AUTOSAR XML (schema 4-0-3)
package /ComponentTypes
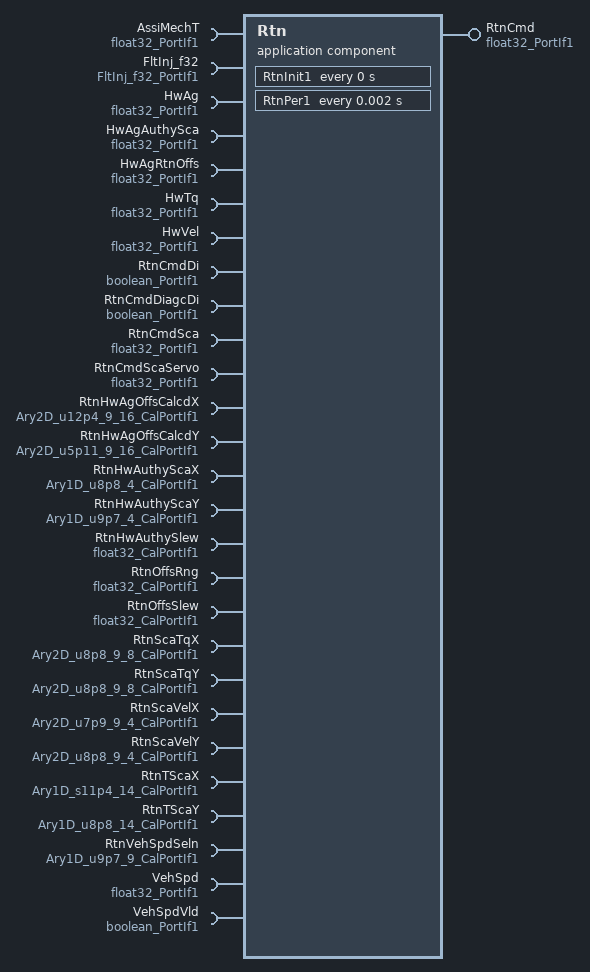
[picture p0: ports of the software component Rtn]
  application sw component type Rtn
    provide port RtnCmd: nonqueued-sender-com-spec{data-element=Val, init-value=0}, provided-interface=float32_PortIf1
    27 x require port:
      AssiMechT: nonqueued-receiver-com-spec{data-element=Val, filter=data-filter-type=ALWAYS, init-value=0}, required-interface=float32_PortIf1
      FltInj_f32: client-com-spec=Oper, required-interface=FltInj_f32_PortIf1
      HwAg: nonqueued-receiver-com-spec{data-element=Val, filter=data-filter-type=ALWAYS, init-value=0}, required-interface=float32_PortIf1
      HwAgAuthySca: nonqueued-receiver-com-spec{data-element=Val, filter=data-filter-type=ALWAYS, init-value=0}, required-interface=float32_PortIf1
      HwAgRtnOffs: nonqueued-receiver-com-spec{data-element=Val, filter=data-filter-type=ALWAYS, init-value=0}, required-interface=float32_PortIf1
      HwTq: nonqueued-receiver-com-spec{data-element=Val, filter=data-filter-type=ALWAYS, init-value=0}, required-interface=float32_PortIf1
      HwVel: nonqueued-receiver-com-spec{data-element=Val, filter=data-filter-type=ALWAYS, init-value=0}, required-interface=float32_PortIf1
      RtnCmdDi: nonqueued-receiver-com-spec{data-element=Logl, filter=data-filter-type=ALWAYS, init-value=0}, required-interface=boolean_PortIf1
      RtnCmdDiagcDi: nonqueued-receiver-com-spec{data-element=Logl, filter=data-filter-type=ALWAYS, init-value=1}, required-interface=boolean_PortIf1
      RtnCmdSca: nonqueued-receiver-com-spec{data-element=Val, filter=data-filter-type=ALWAYS, init-value=1}, required-interface=float32_PortIf1
      RtnCmdScaServo: nonqueued-receiver-com-spec{data-element=Val, filter=data-filter-type=ALWAYS, init-value=1}, required-interface=float32_PortIf1
      RtnHwAgOffsCalcdX: parameter-require-com-spec{init-value=9 x [0, 8, 16, 80, 160, 320, 480, 720, 960, 1440, 1920, 2880, 4320, 5760, 7200, 8640], parameter=Ary2D}, required-interface=Ary2D_u12p4_9_16_CalPortIf1
      RtnHwAgOffsCalcdY: parameter-require-com-spec{init-value=9 x 16 x 0, parameter=Ary2D}, required-interface=Ary2D_u5p11_9_16_CalPortIf1
      RtnHwAuthyScaX: parameter-require-com-spec{init-value=[0, 128, 192, 256], parameter=Ary1D}, required-interface=Ary1D_u8p8_4_CalPortIf1
      RtnHwAuthyScaY: parameter-require-com-spec{init-value=[0, 0, 0, 128], parameter=Ary1D}, required-interface=Ary1D_u9p7_4_CalPortIf1
      RtnHwAuthySlew: parameter-require-com-spec{init-value=0.5, parameter=Val}, required-interface=float32_CalPortIf1
      RtnOffsRng: parameter-require-com-spec{init-value=17, parameter=Val}, required-interface=float32_CalPortIf1
      RtnOffsSlew: parameter-require-com-spec{init-value=0.04, parameter=Val}, required-interface=float32_CalPortIf1
      RtnScaTqX: parameter-require-com-spec{init-value=9 x [0, 128, 256, 512, 768, 1024, 1280, 2560], parameter=Ary2D}, required-interface=Ary2D_u8p8_9_8_CalPortIf1
      RtnScaTqY: parameter-require-com-spec{init-value=9 x 8 x 256, parameter=Ary2D}, required-interface=Ary2D_u8p8_9_8_CalPortIf1
      RtnScaVelX: parameter-require-com-spec{init-value=9 x [0, 20480, 21504, 21504], parameter=Ary2D}, required-interface=Ary2D_u7p9_9_4_CalPortIf1
      RtnScaVelY: parameter-require-com-spec{init-value=9 x [256, 256, 256, 256], parameter=Ary2D}, required-interface=Ary2D_u8p8_9_4_CalPortIf1
      RtnTScaX: parameter-require-com-spec{init-value=[-640, -560, -480, -320, -160, 0, 160, 320, 480, 640, 800, 960, 1120, 1440], parameter=Ary1D}, required-interface=Ary1D_s11p4_14_CalPortIf1
      RtnTScaY: parameter-require-com-spec{init-value=14 x 256, parameter=Ary1D}, required-interface=Ary1D_u8p8_14_CalPortIf1
      RtnVehSpdSeln: parameter-require-com-spec{init-value=[0, 384, 896, 1536, 2560, 3840, 5760, 7680, 10240], parameter=Ary1D}, required-interface=Ary1D_u9p7_9_CalPortIf1
      VehSpd: nonqueued-receiver-com-spec{data-element=Val, filter=data-filter-type=ALWAYS, init-value=0}, required-interface=float32_PortIf1
      VehSpdVld: nonqueued-receiver-com-spec{data-element=Logl, filter=data-filter-type=ALWAYS, init-value=0}, required-interface=boolean_PortIf1
    behavior Rtn_InternalBehavior
      ar-typed-per-instance-memorys:
        9 x data, all with sw-calibration-access=READ-ONLY, type=float32:
          dRtnAbsltHwAg
          dRtnAssiMechTRtnSca
          dRtnBascRtn
          dRtnHwAgAuthySca
          dRtnHwAgRtnCmd
          dRtnHwTqRtnSca
          dRtnHwVelRtnSca
          PrevHwAgAuthy
          PrevHwAgOffsLimd
      timing event Rtn_InitEvent: start-on-event=RtnInit1, period=0
      timing event TMT_RtnPer1: start-on-event=RtnPer1, period=0.002
      port-api-options:
        enable-take-address=false, indirect-api=false, port=RtnCmdDiagcDi
        enable-take-address=false, indirect-api=false, port=RtnCmdSca
      runnable RtnInit1
      runnable RtnPer1
        data-receive-point-by-arguments:
          12 x access:
            REC_AssiMechT_Val: accessed-variable=AssiMechT.Val
            REC_HwAg_Val: accessed-variable=HwAg.Val
            REC_HwAgAuthySca_Val: accessed-variable=HwAgAuthySca.Val
            REC_HwAgRtnOffs_Val: accessed-variable=HwAgRtnOffs.Val
            REC_HwTq_Val: accessed-variable=HwTq.Val
            REC_HwVel_Val: accessed-variable=HwVel.Val
            REC_RtnCmdDi_Logl: accessed-variable=RtnCmdDi.Logl
            REC_RtnCmdDiagcDi_Logl: accessed-variable=RtnCmdDiagcDi.Logl
            REC_RtnCmdSca_Val: accessed-variable=RtnCmdSca.Val
            REC_RtnCmdScaServo_Val: accessed-variable=RtnCmdScaServo.Val
            REC_VehSpd_Val: accessed-variable=VehSpd.Val
            REC_VehSpdVld_Logl: accessed-variable=VehSpdVld.Logl
        data-send-points:
          access SEND_RtnCmd_Val: accessed-variable=RtnCmd.Val
        sync call SC_FltInj_f32_Oper: operation=FltInj_f32.Oper, timeout=0
  swc implementation Rtn_Implementation: behavior=Rtn_InternalBehavior
    code-descriptors:
      code Default: artifact-descriptors=autosar-engineering-object={short-label=Default, category=SWSRC}
